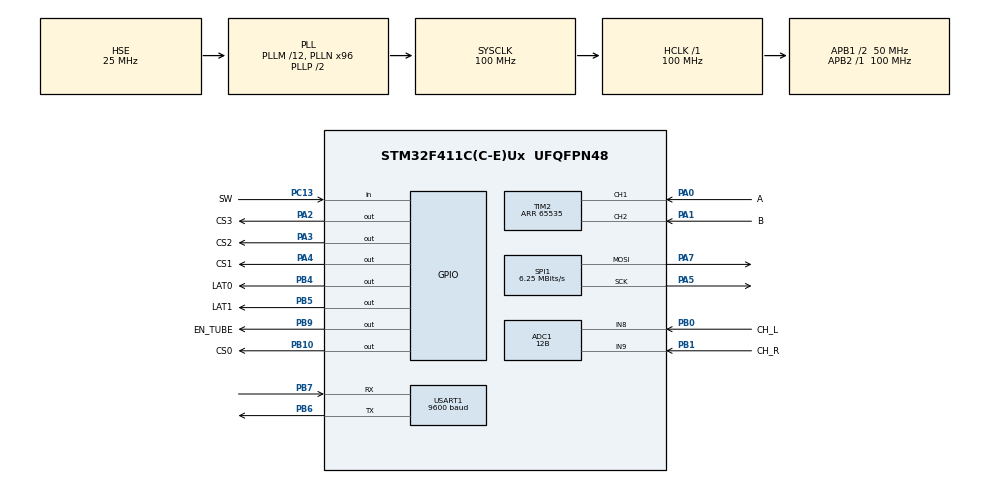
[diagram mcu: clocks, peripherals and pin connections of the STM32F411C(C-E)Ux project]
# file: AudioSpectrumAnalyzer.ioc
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ADC1.Channel-12\#ChannelRegularConversion=ADC_CHANNEL_9
ADC1.Channel-13\#ChannelRegularConversion=ADC_CHANNEL_8
ADC1.ClockPrescaler=ADC_CLOCK_SYNC_PCLK_DIV4
ADC1.ContinuousConvMode=DISABLE
ADC1.DMAContinuousRequests=ENABLE
ADC1.ExternalTrigConv=ADC_EXTERNALTRIGCONV_T3_TRGO
ADC1.NbrOfConversion=2
ADC1.NbrOfConversionFlag=1
ADC1.Rank-12\#ChannelRegularConversion=1
ADC1.Rank-13\#ChannelRegularConversion=2
ADC1.Resolution=ADC_RESOLUTION_12B
ADC1.SamplingTime-12\#ChannelRegularConversion=ADC_SAMPLETIME_144CYCLES
ADC1.SamplingTime-13\#ChannelRegularConversion=ADC_SAMPLETIME_144CYCLES
ADC1.ScanConvMode=ENABLE
ADC1.master=1
Dma.ADC1.0.Direction=DMA_PERIPH_TO_MEMORY
Dma.ADC1.0.FIFOMode=DMA_FIFOMODE_DISABLE
Dma.ADC1.0.Instance=DMA2_Stream0
Dma.ADC1.0.MemDataAlignment=DMA_MDATAALIGN_HALFWORD
Dma.ADC1.0.MemInc=DMA_MINC_ENABLE
Dma.ADC1.0.Mode=DMA_CIRCULAR
Dma.ADC1.0.PeriphDataAlignment=DMA_PDATAALIGN_HALFWORD
Dma.ADC1.0.PeriphInc=DMA_PINC_DISABLE
Dma.ADC1.0.Priority=DMA_PRIORITY_LOW
Dma.Request0=ADC1
Mcu.Family=STM32F4
Mcu.Name=STM32F411C(C-E)Ux
Mcu.Package=UFQFPN48
NVIC.DMA2_Stream0_IRQn=true\:1\:0\:true\:false\:true\:false\:true\:true
NVIC.PriorityGroup=NVIC_PRIORITYGROUP_4
NVIC.TIM4_IRQn=true\:2\:0\:true\:false\:true\:true\:true\:true
PA0-WKUP.GPIO_Label=A
PA0-WKUP.Signal=S_TIM2_CH1_ETR
PA1.GPIO_Label=B
PA1.Signal=S_TIM2_CH2
PA2.GPIO_Label=CS3
PA2.PinState=GPIO_PIN_SET
PA2.Signal=GPIO_Output
PA3.GPIO_Label=CS2
PA3.PinState=GPIO_PIN_SET
PA3.Signal=GPIO_Output
PA4.GPIO_Label=CS1
PA4.PinState=GPIO_PIN_SET
PA4.Signal=GPIO_Output
PA5.Mode=TX_Only_Simplex_Unidirect_Master
PA5.Signal=SPI1_SCK
PA7.Mode=TX_Only_Simplex_Unidirect_Master
PA7.Signal=SPI1_MOSI
PB0.GPIO_Label=CH_L
PB0.Signal=ADCx_IN8
PB1.GPIO_Label=CH_R
PB1.Signal=ADCx_IN9
PB10.GPIO_Label=CS0
PB10.PinState=GPIO_PIN_SET
PB10.Signal=GPIO_Output
PB4.GPIO_Label=LAT0
PB4.PinState=GPIO_PIN_SET
PB4.Signal=GPIO_Output
PB5.GPIO_Label=LAT1
PB5.PinState=GPIO_PIN_SET
PB5.Signal=GPIO_Output
PB6.Mode=Asynchronous
PB6.Signal=USART1_TX
PB7.Mode=Asynchronous
PB7.Signal=USART1_RX
PB9.GPIO_Label=EN_TUBE
PB9.Signal=GPIO_Output
PC13-ANTI_TAMP.GPIO_Label=SW
PC13-ANTI_TAMP.Signal=GPIO_Input
PC14-OSC32_IN.Mode=LSE-External-Oscillator
PC14-OSC32_IN.Signal=RCC_OSC32_IN
PC15-OSC32_OUT.Mode=LSE-External-Oscillator
PC15-OSC32_OUT.Signal=RCC_OSC32_OUT
PH0\ -\ OSC_IN.Mode=HSE-External-Oscillator
PH0\ -\ OSC_IN.Signal=RCC_OSC_IN
PH1\ -\ OSC_OUT.Mode=HSE-External-Oscillator
PH1\ -\ OSC_OUT.Signal=RCC_OSC_OUT
ProjectManager.HeapSize=0x200
ProjectManager.StackSize=0x400
ProjectManager.TargetToolchain=Makefile
RCC.48MHZClocksFreq_Value=50000000
RCC.AHBFreq_Value=100000000
RCC.APB1CLKDivider=RCC_HCLK_DIV2
RCC.APB1Freq_Value=50000000
RCC.APB1TimFreq_Value=100000000
RCC.APB2Freq_Value=100000000
RCC.APB2TimFreq_Value=100000000
RCC.CortexFreq_Value=100000000
RCC.HCLKFreq_Value=100000000
RCC.HSE_VALUE=25000000
RCC.HSI_VALUE=16000000
RCC.PLLM=12
RCC.PLLN=96
RCC.PLLSourceVirtual=RCC_PLLSOURCE_HSE
RCC.SYSCLKFreq_VALUE=100000000
RCC.SYSCLKSource=RCC_SYSCLKSOURCE_PLLCLK
RCC.VCOOutputFreq_Value=200000000
SH.ADCx_IN8.0=ADC1_IN8,IN8
SH.ADCx_IN9.0=ADC1_IN9,IN9
SH.S_TIM2_CH1_ETR.0=TIM2_CH1,Encoder_Interface
SH.S_TIM2_CH2.0=TIM2_CH2,Encoder_Interface
SPI1.BaudRatePrescaler=SPI_BAUDRATEPRESCALER_16
SPI1.CalculateBaudRate=6.25 MBits/s
SPI1.Direction=SPI_DIRECTION_2LINES
SPI1.Mode=SPI_MODE_MASTER
SPI1.VirtualType=VM_MASTER
TIM1.Prescaler=100
TIM2.EncoderMode=TIM_ENCODERMODE_TI12
TIM2.IC2Filter=15
TIM2.Period=65535
TIM3.Period=1
TIM3.Prescaler=999
TIM3.TIM_MasterOutputTrigger=TIM_TRGO_UPDATE
TIM4.AutoReloadPreload=TIM_AUTORELOAD_PRELOAD_ENABLE
TIM4.Period=99
TIM4.Prescaler=999
USART1.BaudRate=9600
USART1.Mode=MODE_TX_RX
USART1.VirtualMode=VM_ASYNC
VP_ADC1_Vbat_Input.Mode=IN-Vbat
VP_RTC_VS_RTC_Activate.Mode=RTC_Enabled
VP_TIM1_VS_ClockSourceINT.Mode=Internal
VP_TIM3_VS_ClockSourceINT.Mode=Internal
VP_TIM4_VS_ClockSourceINT.Mode=Internal
board=custom

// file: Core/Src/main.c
/* USER CODE BEGIN Header */
/**
  ******************************************************************************
  * @file           : main.c
  * @brief          : Main program body
  ******************************************************************************
  * @attention
  *
  * Copyright (c) 2023 STMicroelectronics.
  * All rights reserved.
  *
  * This software is licensed under terms that can be found in the LICENSE file
  * in the root directory of this software component.
  * If no LICENSE file comes with this software, it is provided AS-IS.
  *
  ******************************************************************************
  */
/* USER CODE END Header */
#include "main.h"
#include "adc.h"
#include "dma.h"
#include "rtc.h"
#include "spi.h"
#include "tim.h"
#include "usart.h"
#include "gpio.h"

/* USER CODE BEGIN Includes */
#include "clean_main.h"
/* USER CODE END Includes */

void SystemClock_Config(void);

int main(void)
{

  /* MCU Configuration--------------------------------------------------------*/

  /* Reset of all peripherals, Initializes the Flash interface and the Systick. */
  HAL_Init();

  /* Configure the system clock */
  SystemClock_Config();

  /* Initialize all configured peripherals */
  MX_GPIO_Init();
  MX_DMA_Init();
  MX_ADC1_Init();
  MX_SPI1_Init();
  MX_TIM2_Init();
  MX_USART1_UART_Init();
  MX_TIM1_Init();
  MX_TIM3_Init();
  MX_TIM4_Init();
  MX_RTC_Init();
  /* USER CODE BEGIN 2 */
  clean_main();
  /* USER CODE END 2 */

  /* Infinite loop */
  /* USER CODE BEGIN WHILE */
  while (1)
  {
    clean_loop();
    /* USER CODE END WHILE */

  }
}

void SystemClock_Config(void)
{
  RCC_OscInitTypeDef RCC_OscInitStruct = {0};
  RCC_ClkInitTypeDef RCC_ClkInitStruct = {0};

  /** Configure the main internal regulator output voltage
  */
  __HAL_RCC_PWR_CLK_ENABLE();
  __HAL_PWR_VOLTAGESCALING_CONFIG(PWR_REGULATOR_VOLTAGE_SCALE1);

  /** Initializes the RCC Oscillators according to the specified parameters
  * in the RCC_OscInitTypeDef structure.
  */
  RCC_OscInitStruct.OscillatorType = RCC_OSCILLATORTYPE_LSI|RCC_OSCILLATORTYPE_HSE;
  RCC_OscInitStruct.HSEState = RCC_HSE_ON;
  RCC_OscInitStruct.LSIState = RCC_LSI_ON;
  RCC_OscInitStruct.PLL.PLLState = RCC_PLL_ON;
  RCC_OscInitStruct.PLL.PLLSource = RCC_PLLSOURCE_HSE;
  RCC_OscInitStruct.PLL.PLLM = 12;
  RCC_OscInitStruct.PLL.PLLN = 96;
  RCC_OscInitStruct.PLL.PLLP = RCC_PLLP_DIV2;
  RCC_OscInitStruct.PLL.PLLQ = 4;
  if (HAL_RCC_OscConfig(&RCC_OscInitStruct) != HAL_OK)
  {
    Error_Handler();
  }

  /** Initializes the CPU, AHB and APB buses clocks
  */
  RCC_ClkInitStruct.ClockType = RCC_CLOCKTYPE_HCLK|RCC_CLOCKTYPE_SYSCLK
                              |RCC_CLOCKTYPE_PCLK1|RCC_CLOCKTYPE_PCLK2;
  RCC_ClkInitStruct.SYSCLKSource = RCC_SYSCLKSOURCE_PLLCLK;
  RCC_ClkInitStruct.AHBCLKDivider = RCC_SYSCLK_DIV1;
  RCC_ClkInitStruct.APB1CLKDivider = RCC_HCLK_DIV2;
  RCC_ClkInitStruct.APB2CLKDivider = RCC_HCLK_DIV1;

  if (HAL_RCC_ClockConfig(&RCC_ClkInitStruct, FLASH_LATENCY_3) != HAL_OK)
  {
    Error_Handler();
  }
}

void Error_Handler(void)
{
  __disable_irq();
  while (1)
  {
  }
}
